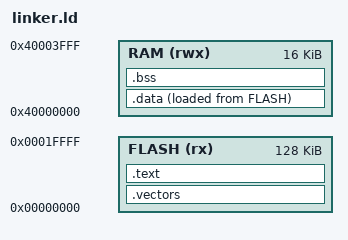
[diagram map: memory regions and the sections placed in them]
ENTRY(_start)

MEMORY
{
    FLASH (rx)  : ORIGIN = 0x00000000, LENGTH = 128K
    RAM   (rwx) : ORIGIN = 0x40000000, LENGTH = 16K
}

_stack_top = ORIGIN(RAM) + LENGTH(RAM);

SECTIONS
{
    .vectors :
    {
        KEEP(*(.vectors))
    } > FLASH

    .text :
    {
        *(.text.startup)
        *(.text*)
        *(.rodata*)
        . = ALIGN(4);
    } > FLASH

    .data :
    {
        . = ALIGN(4);
        _sdata = .;
        *(.data*)
        . = ALIGN(4);
        _edata = .;
    } > RAM AT > FLASH

    _sidata = LOADADDR(.data);

    .bss (NOLOAD) :
    {
        . = ALIGN(4);
        _sbss = .;
        *(.bss*)
        *(COMMON)
        . = ALIGN(4);
        _ebss = .;
    } > RAM
}
